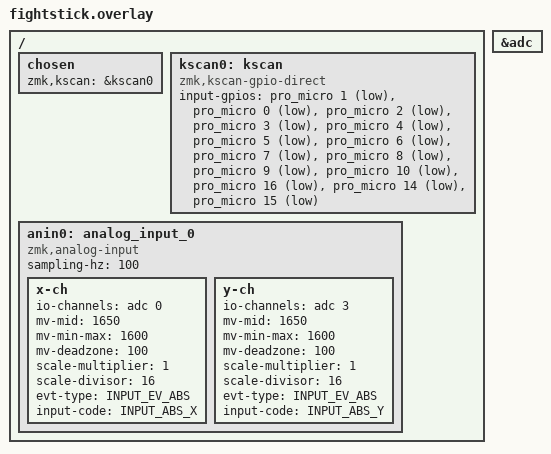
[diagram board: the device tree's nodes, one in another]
#include <dt-bindings/zmk/matrix_transform.h>
#include <zephyr/dt-bindings/input/input-event-codes.h>

/ {
    chosen {
        zmk,kscan = &kscan0;
    };

    kscan0: kscan {
        compatible = "zmk,kscan-gpio-direct";
        
        input-gpios
            /* Action buttons */
            = <&pro_micro 1 (GPIO_ACTIVE_LOW | GPIO_PULL_UP)>   // D1 - Square
            , <&pro_micro 0 (GPIO_ACTIVE_LOW | GPIO_PULL_UP)>   // D0 - Triangle  
            , <&pro_micro 2 (GPIO_ACTIVE_LOW | GPIO_PULL_UP)>   // D2 - R1
            , <&pro_micro 3 (GPIO_ACTIVE_LOW | GPIO_PULL_UP)>   // D3 - L1
            , <&pro_micro 4 (GPIO_ACTIVE_LOW | GPIO_PULL_UP)>   // D4 - Cross
            , <&pro_micro 5 (GPIO_ACTIVE_LOW | GPIO_PULL_UP)>   // D5 - Circle
            , <&pro_micro 6 (GPIO_ACTIVE_LOW | GPIO_PULL_UP)>   // D6 - R2
            , <&pro_micro 7 (GPIO_ACTIVE_LOW | GPIO_PULL_UP)>   // D7 - L2
            
            /* D-pad */
            , <&pro_micro 8 (GPIO_ACTIVE_LOW | GPIO_PULL_UP)>   // D8 - Up
            , <&pro_micro 9 (GPIO_ACTIVE_LOW | GPIO_PULL_UP)>   // D9 - Down
            , <&pro_micro 10 (GPIO_ACTIVE_LOW | GPIO_PULL_UP)>  // D10 - Left
            , <&pro_micro 16 (GPIO_ACTIVE_LOW | GPIO_PULL_UP)>  // D16 - Right
            
            /* System buttons */
            , <&pro_micro 14 (GPIO_ACTIVE_LOW | GPIO_PULL_UP)>  // D14 - Start
            , <&pro_micro 15 (GPIO_ACTIVE_LOW | GPIO_PULL_UP)>  // D15 - Select
            ;
    };

    /* Analog joystick configuration */
    anin0: analog_input_0 {
        compatible = "zmk,analog-input";
        sampling-hz = <100>;
        
        /* X-axis configuration */
        x-ch {
            io-channels = <&adc 0>;  // A0/P0.02 on nice!nano v2
            mv-mid = <1650>;         // Center voltage (3.3V/2 = 1650mV)
            mv-min-max = <1600>;     // Range from center to min/max
            mv-deadzone = <100>;     // Deadzone in mV
            scale-multiplier = <1>;
            scale-divisor = <16>;
            evt-type = <INPUT_EV_ABS>;
            input-code = <INPUT_ABS_X>;
        };
        
        /* Y-axis configuration */
        y-ch {
            io-channels = <&adc 3>;  // A1/P0.29 on nice!nano v2
            mv-mid = <1650>;
            mv-min-max = <1600>;
            mv-deadzone = <100>;
            scale-multiplier = <1>;
            scale-divisor = <16>;
            evt-type = <INPUT_EV_ABS>;
            input-code = <INPUT_ABS_Y>;
        };
    };
};

/* ADC configuration for nice!nano v2 */
&adc {
    status = "okay";
};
